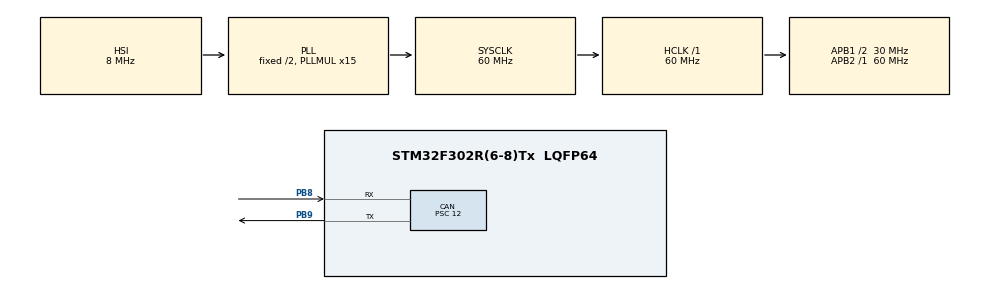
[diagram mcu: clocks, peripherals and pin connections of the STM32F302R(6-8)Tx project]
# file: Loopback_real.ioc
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CAN.BS1=CAN_BS1_3TQ
CAN.CalculateBaudRate=500000
CAN.CalculateTimeBit=2000
CAN.CalculateTimeQuantum=400.0
CAN.Mode=CAN_MODE_LOOPBACK
CAN.Prescaler=12
Mcu.Family=STM32F3
Mcu.Name=STM32F302R(6-8)Tx
Mcu.Package=LQFP64
NVIC.PriorityGroup=NVIC_PRIORITYGROUP_4
NVIC.USB_LP_CAN_RX0_IRQn=true\:0\:0\:false\:false\:true\:true\:true\:true
PA13.Mode=Serial_Wire
PA13.Signal=SYS_JTMS-SWDIO
PA14.Mode=Serial_Wire
PA14.Signal=SYS_JTCK-SWCLK
PB8.Mode=CAN_Activate
PB8.Signal=CAN_RX
PB9.Mode=CAN_Activate
PB9.Signal=CAN_TX
PC14\ -\ OSC32_IN.Mode=LSE-External-Oscillator
PC14\ -\ OSC32_IN.Signal=RCC_OSC32_IN
PC15\ -\ OSC32_OUT.Mode=LSE-External-Oscillator
PC15\ -\ OSC32_OUT.Signal=RCC_OSC32_OUT
PF0-OSC_IN.Mode=HSE-External-Oscillator
PF0-OSC_IN.Signal=RCC_OSC_IN
PF1-OSC_OUT.Mode=HSE-External-Oscillator
PF1-OSC_OUT.Signal=RCC_OSC_OUT
ProjectManager.HeapSize=0x200
ProjectManager.StackSize=0x400
ProjectManager.TargetToolchain=STM32CubeIDE
RCC.AHBFreq_Value=60000000
RCC.APB1CLKDivider=RCC_HCLK_DIV2
RCC.APB1Freq_Value=30000000
RCC.APB1TimFreq_Value=60000000
RCC.APB2Freq_Value=60000000
RCC.APB2TimFreq_Value=60000000
RCC.CortexFreq_Value=60000000
RCC.HCLKFreq_Value=60000000
RCC.HSE_VALUE=8000000
RCC.HSI_VALUE=8000000
RCC.PLLMUL=RCC_PLL_MUL15
RCC.SYSCLKFreq_VALUE=60000000
RCC.SYSCLKSourceVirtual=RCC_SYSCLKSOURCE_PLLCLK
RCC.USBFreq_Value=60000000
board=custom

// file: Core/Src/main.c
/* USER CODE BEGIN Header */
/**
  ******************************************************************************
  * @file           : main.c
  * @brief          : Main program body
  ******************************************************************************
  * @attention
  *
  * Copyright (c) 2024 STMicroelectronics.
  * All rights reserved.
  *
  * This software is licensed under terms that can be found in the LICENSE file
  * in the root directory of this software component.
  * If no LICENSE file comes with this software, it is provided AS-IS.
  *
  ******************************************************************************
  */
/* USER CODE END Header */

#include "main.h"

CAN_HandleTypeDef hcan; // Handle for CAN interface

void SystemClock_Config(void);
static void MX_GPIO_Init(void);
static void MX_CAN_Init(void);

/* USER CODE BEGIN 0 */
CAN_TxHeaderTypeDef tx_header; // CAN transmit header
CAN_RxHeaderTypeDef rx_header; // CAN receive header

uint32_t tx_mailbox;
uint8_t tx_data[8];
uint8_t rx_data[8];

uint8_t count = 0;

// Callback for message pending in receive FIFO 0
void HAL_CAN_RxFifo0MsgPendingCallback(CAN_HandleTypeDef *hcan){
	HAL_CAN_GetRxMessage(hcan, CAN_RX_FIFO0, &rx_header, rx_data);
}
/* USER CODE END 0 */

int main(void)
{
  /* MCU Configuration--------------------------------------------------------*/

  /* Reset of all peripherals, Initializes the Flash interface and the Systick. */
  HAL_Init();

  /* Configure the system clock */
  SystemClock_Config();

  /* Initialize all configured peripherals */
  MX_GPIO_Init();
  MX_CAN_Init();

  /* USER CODE BEGIN 2 */
    HAL_CAN_Start(&hcan); // Start CAN communication
    HAL_CAN_ActivateNotification(&hcan, CAN_IT_RX_FIFO0_MSG_PENDING); // Enable notifications

    // Setup CAN transmit header
    tx_header.DLC = 1; //Data length
    tx_header.ExtId = 0; //Extended ID
    tx_header.IDE = CAN_ID_STD;
    tx_header.RTR = CAN_RTR_DATA;
    tx_header.StdId = 0x069; // ID used by microcontroller
    tx_header.TransmitGlobalTime = DISABLE;
  /* USER CODE END 2 */

  /* Infinite loop */
  /* USER CODE BEGIN WHILE */
    uint8_t value = 0;

    while (1)
    {
        // Prepare and send CAN message
	    tx_data[0] = value; // Assign value to data array
	    HAL_CAN_AddTxMessage(&hcan, &tx_header, tx_data, &tx_mailbox); // Send CAN message
	    value++; // Increment value for next transmission
	    HAL_Delay(100);
    }
  /* USER CODE END WHILE */

}

void SystemClock_Config(void)
{
  RCC_OscInitTypeDef RCC_OscInitStruct = {0};
  RCC_ClkInitTypeDef RCC_ClkInitStruct = {0};

  /** Configure the main internal regulator output voltage */
  RCC_OscInitStruct.OscillatorType = RCC_OSCILLATORTYPE_HSI;
  RCC_OscInitStruct.HSIState = RCC_HSI_ON;
  RCC_OscInitStruct.HSICalibrationValue = RCC_HSICALIBRATION_DEFAULT;
  RCC_OscInitStruct.PLL.PLLState = RCC_PLL_ON;
  RCC_OscInitStruct.PLL.PLLSource = RCC_PLLSOURCE_HSI;
  RCC_OscInitStruct.PLL.PLLMUL = RCC_PLL_MUL15;
  if (HAL_RCC_OscConfig(&RCC_OscInitStruct) != HAL_OK)
  {
    Error_Handler();
  }

  /** Configure the clock for CPU, AHB, and APB buses */
  RCC_ClkInitStruct.ClockType = RCC_CLOCKTYPE_HCLK|RCC_CLOCKTYPE_SYSCLK
                              |RCC_CLOCKTYPE_PCLK1|RCC_CLOCKTYPE_PCLK2;
  RCC_ClkInitStruct.SYSCLKSource = RCC_SYSCLKSOURCE_PLLCLK;
  RCC_ClkInitStruct.AHBCLKDivider = RCC_SYSCLK_DIV1;
  RCC_ClkInitStruct.APB1CLKDivider = RCC_HCLK_DIV2;
  RCC_ClkInitStruct.APB2CLKDivider = RCC_HCLK_DIV1;

  if (HAL_RCC_ClockConfig(&RCC_ClkInitStruct, FLASH_LATENCY_2) != HAL_OK)
  {
    Error_Handler();
  }
}

static void MX_CAN_Init(void)
{
  hcan.Instance = CAN;
  hcan.Init.Prescaler = 12;
  hcan.Init.Mode = CAN_MODE_LOOPBACK; // Configured in loopback mode for testing
  hcan.Init.SyncJumpWidth = CAN_SJW_1TQ;
  hcan.Init.TimeSeg1 = CAN_BS1_3TQ;
  hcan.Init.TimeSeg2 = CAN_BS2_1TQ;
  hcan.Init.TimeTriggeredMode = DISABLE;
  hcan.Init.AutoBusOff = DISABLE;
  hcan.Init.AutoWakeUp = DISABLE;
  hcan.Init.AutoRetransmission = DISABLE;
  hcan.Init.ReceiveFifoLocked = DISABLE;
  hcan.Init.TransmitFifoPriority = DISABLE;
  if (HAL_CAN_Init(&hcan) != HAL_OK)
  {
    Error_Handler();
  }
}

static void MX_GPIO_Init(void)
{
  /* GPIO Ports Clock Enable */
  __HAL_RCC_GPIOC_CLK_ENABLE();
  __HAL_RCC_GPIOF_CLK_ENABLE();
  __HAL_RCC_GPIOA_CLK_ENABLE();
  __HAL_RCC_GPIOB_CLK_ENABLE();
}

void Error_Handler(void)
{
  __disable_irq();
  while (1)
  {
  }
}
